# AE822FA0E5597BS0_CM55_HE_View register map
Vendor: Alif Semiconductor; Series: E8; File version: 1.0
CPU: CM55 r1p0, selectable endian, MPU, FPU, double-precision FPU, DSP, VTOR, 8 interrupt priority bits, 1 SAU regions
Registers are 32-bit, read-write, reset 0x0 unless marked. A register's access mark holds for its fields unless they carry their own. Offsets are from the block's base; [hi:lo] are bit positions; {n}, {i} and the like mark numbered series.

## USB (part 1 of 2)
Base 0x48200000
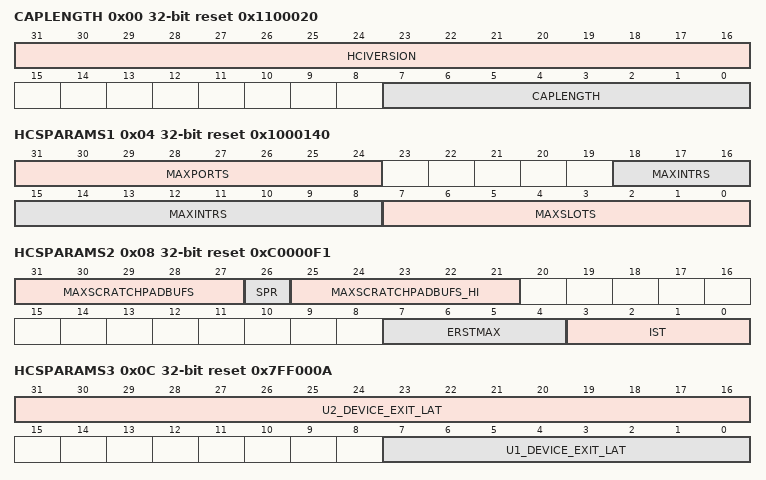
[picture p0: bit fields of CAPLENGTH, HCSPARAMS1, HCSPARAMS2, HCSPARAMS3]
0x00 CAPLENGTH ro reset 0x1100020 — Capability Registers Length
  [31:16] HCIVERSION — Host controller interface version number.
  [7:0] CAPLENGTH — Capability registers length.
0x04 HCSPARAMS1 ro reset 0x1000140 — Structural Parameters 1 Register
  [31:24] MAXPORTS — Number of ports.
  [18:8] MAXINTRS — Number of interrupters.
  [7:0] MAXSLOTS — Number of device slots.
0x08 HCSPARAMS2 ro reset 0xC0000F1 — Structural Parameters 2 Register
  [31:27] MAXSCRATCHPADBUFS — Maximum scratchpad buffers low. Possible values are from 0x1 to 0x4.
  [26] SPR — Scratchpad restore.
  [25:21] MAXSCRATCHPADBUFS_HI — Maximum scratchpad buffers high.
  [7:4] ERSTMAX — Event ring segment table maximum.
  [3:0] IST — Isochronous scheduling threshold.
0x0C HCSPARAMS3 ro reset 0x7FF000A — Structural Parameters 3 Register
  [31:16] U2_DEVICE_EXIT_LAT — U2 device exit latency.
  [7:0] U1_DEVICE_EXIT_LAT — U1 device exit latency.
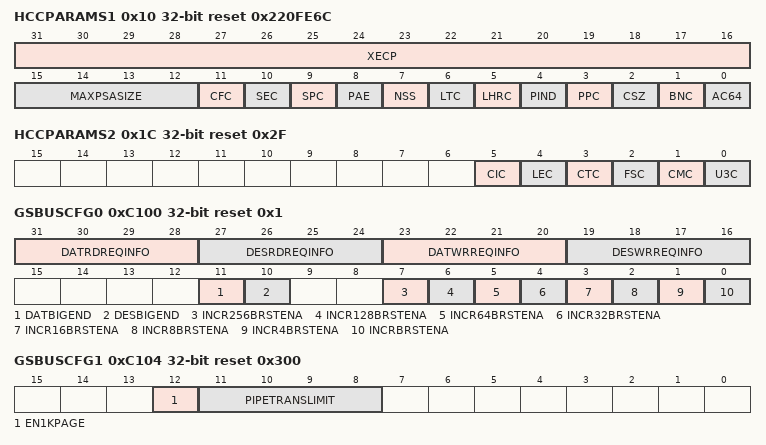
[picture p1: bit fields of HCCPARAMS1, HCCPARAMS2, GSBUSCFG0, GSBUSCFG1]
0x10 HCCPARAMS1 ro reset 0x220FE6C — Capability Parameters 1 Register
  [31:16] XECP — xHCI extended capabilities pointer.
  [15:12] MAXPSASIZE — Maximum primary stream array size.
  [11] CFC — Contiguous frame ID capability.
  [10] SEC — Stopped EDLTA capability.
  [9] SPC — Short packet capability.
  [8] PAE — Parse all event data.
  [7] NSS — No secondary SID support.
  [6] LTC — Latency tolerance messaging capability.
  [5] LHRC — Light host controller reset capability.
  [4] PIND — Port indicators.
  [3] PPC — Port power control.
  [2] CSZ — Context size.
  [1] BNC — Bandwidth negotiation capability.
  [0] AC64 — 64-bit addressing capability.
0x14 DBOFF ro reset 0x480 — Doorbell Offset
  [31:2] DOORBELL_ARRAY_OFFSET
0x18 RTSOFF ro reset 0x440 — Run-time Register Space Offset
  [31:5] RUNTIME_REG_SPACE_OFFSET — Runtime register space offset.
0x1C HCCPARAMS2 ro reset 0x2F — Host Controller Capability Parameters 2
  [5] CIC — Configuration information capability.
  [4] LEC — Large ESIT payload capability.
  [3] CTC — Compliance transition capability.
  [2] FSC — Force save context capability.
  [1] CMC — Configure endpoint command maximum exit latency too large capability.
  [0] U3C — U3 entry capability.
0xC100 GSBUSCFG0 reset 0x1 — Global SoC Bus Configuration Register 0
  [31:28] DATRDREQINFO — Data read request info. AHB-prot/AXI-cache/OCP-ReqInfo for data read.
  [27:24] DESRDREQINFO — Descriptor read request info. AHB-prot/AXI-cache/OCP-ReqInfo for descriptor read.
  [23:20] DATWRREQINFO — Data write request info. AHB-prot/AXI-cache/OCP-ReqInfo for data write.
  [19:16] DESWRREQINFO — Descriptor write request info. AHB-prot/AXI-cache/OCP-ReqInfo for descriptor write.
  [11] DATBIGEND — Data access is big endian. This bit controls the endian mode for data accesses. Note: For an AXI master, this bit must be set to 0x0.
    0=Little-endian (default); 1=Big-endian
  [10] DESBIGEND — Descriptor access is big endian. This bit controls the endian mode for descriptor accesses. Data is considered as embedded data in the descriptors in the following cases: - Device mode: The buffer pointer of a Setup TRB points to the Setup TRB itself. In device mode, if the system uses different endian modes for descriptor and data, software must not use embedded data. - Host mode: The Immediate Data (IDT) bit in a Transfer TRB is set to 0x1. In host mode, if the system uses different endian modes for data and descriptors, the controller treats embedded data as descriptor (not as data) in terms of endian mode handling. If this is not the expectation of the system, the software must manipulate the embedded data accordingly. Note: For an AXI master, this bit must be set to 0x0.
    0=Little-endian (default); 1=Big-endian
  [7] INCR256BRSTENA — INCR256 burst type enable. If software set this bit to 0x1, the AXI master uses INCR to do the 256-beat burst.
  [6] INCR128BRSTENA — INCR128 burst type enable. If software set this bit to 0x1, the AXI master uses INCR to do the 128-beat burst.
  [5] INCR64BRSTENA — INCR64 burst type enable. If software set this bit to 0x1, the AXI master uses INCR to do the 64-beat burst.
  [4] INCR32BRSTENA — INCR32 burst type enable. If software set this bit to 0x1, the AXI master uses INCR to do the 32-beat burst.
  [3] INCR16BRSTENA — INCR16 burst type enable. If software set this bit to 0x1, the AXI master uses INCR to do the 16-beat burst.
  [2] INCR8BRSTENA — INCR8 burst type enable. If software set this bit to 0x0, the AXI master uses INCR to do the 8-beat burst.
  [1] INCR4BRSTENA — INCR4 burst type enable. When this bit is enabled (set to 0x1), the controller is allowed to do bursts of beat length 1, 2, and 4. It is highly recommended that this bit is enabled to prevent descriptor reads and writes from being broken up into separate transfers.
  [0] INCRBRSTENA — Undefined length INCR burst type enable. This bit determines the set of burst lengths the master interface uses. It works in conjunction with the GSBUSCFG0[7-1] bits enables (INCR256/128/64/32/16/8/4). ARLEN/AWLEN do not use INCR except in case of non-aligned burst transfers. In the case of address-aligned transfers, they use only the following burst lengths: - 1 - 2, 4 (if GSBUSCFG0[INCR4BRSTENA] = 0x1) - 8 (if GSBUSCFG0[INCR8BRSTENA] = 0x1) - 16 (if GSBUSCFG0[INCR16BRSTENA] = 0x1) - 32 (if GSBUSCFG0[INCR32BRSTENA] = 0x1) - 64 (if GSBUSCFG0[INCR64BRSTENA] = 0x1) - 128 (if GSBUSCFG0[INCR128BRSTENA] = 0x1) - 256 (if GSBUSCFG0[INCR256BRSTENA] = 0x1) Note: In case of non-address-aligned transfers, INCR may get generated at the beginning and end of the transfers to align the address boundaries, even though INCR is disabled. AXI: ARLEN/AWLEN uses any length less than or equal to the largest-enabled burst length of INCR32/64/128/256.
    0=INCRX burst mode; 1=INCR (undefined length) burst mode
0xC104 GSBUSCFG1 reset 0x300 — Global SoC Bus Configuration Register 1
  [12] EN1KPAGE — 1KB page boundary. By default (this bit is disabled) the AXI breaks transfers at the 4KB page boundary. When this bit is enabled, the AXI master (DMA data) breaks transfers at the 1KB page boundary.
  [11:8] PIPETRANSLIMIT — AXI pipelined transfers burst request limit. This bit field controls the number of outstanding pipelined transfer requests the AXI master pushes to the AXI slave. When the AXI master reaches this limit, it does not make any more requests on the AXI ARADDR and AWADDR buses until the associated data phases complete. This bit field is encoded as follows:
    0=1 request; 1=2 requests; 2=3 requests; 3=4 requests; 15=16 requests
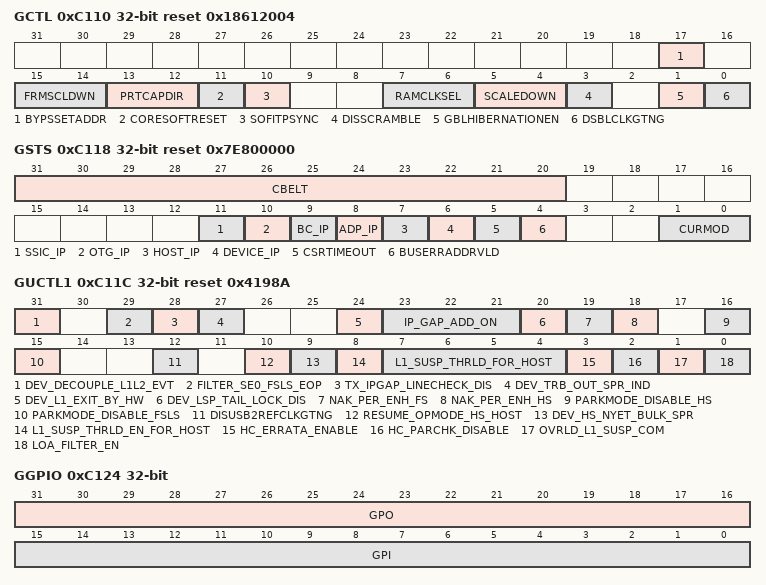
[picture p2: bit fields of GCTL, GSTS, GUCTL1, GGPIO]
0xC110 GCTL reset 0x18612004 — Global Core Control Register
  [17] BYPSSETADDR — Bypass set address in Device mode. This bit must be set to 0x0.
  [15:14] FRMSCLDWN — Frame scales down. This bit field scales down device view of a SOF/USOF/ITP duration. For High Speed (HS) mode: - Value of 3 implements interval to be 15.625 us - Value of 2 implements interval to be 31.25 us - Value of 1 implements interval to be 62.5 us - Value of 0 implements interval to be 125 us
  [13:12] PRTCAPDIR — Port capability direction. Note: For static Host-only/Device-only applications, use DRD Host or DRD Device mode. The combination of this bit filed set to 0x3 with SRP and HNP/RSP disabled is not recommended for these applications. The sequence for switching modes in DRD Device mode is as follows: - For switching from Device to Host: 1. Reset the controller using the CORESOFTRESET bit. 2. Set the PRTCAPDIR bit field to 0x1 (Host mode). 3. Reset the host using USBCMD.HCRESET bit. 4. Follow the steps in Section Initializing Host Registers. - For switching from Host to Device: 1. Reset the controller using the CORESOFTRESET bit. 2. Set the GCTL[PRTCAPDIR] bit field to 0x2 (Device mode). 3. Reset the device by setting the DCTL[CSFTRST] bit. 4. Follow the steps in Section Initializing Registers. Programming this bit field with random data causes the controller to keep toggling between the Host mode and the Device mode. Bit Bash register testing is not recommended.
    1=For host configurations; 2=For device configurations
  [11] CORESOFTRESET — Core soft reset. Clears the interrupts and all the CSRs except the following registers: - GCTL - GUCTL - GSTS - GSNPSID - GUID - GUSB2PHYCFG0 - DCFG - DCTL - DEVTEN - DSTS Note: This bit is for debug purposes only. Use USBCMD.HCRESET bit in xHCI Mode and the DCTL[SOFTRESET] bit in Device mode for soft reset. Programming this bit field with random data will reset the internal logic of the host controller. Due to this side effect Bit Bash register testing is not recommended.
    0=No soft reset; 1=Soft reset to controller
  [10] SOFITPSYNC — Reserved.
  [7:6] RAMCLKSEL — RAM clock (RAM_CLK) select.
    0=AHB bus clock (BUS_CLK); 2=In Host mode, the controller switches RAM_CLK between MAC2_CLK and BUS_CLK based on the status of the USB ports; 3=In Device mode, selects MAC2_CLK as RAM_CLK. In Host mode, controller switches RAM_CLK between MAC2_CLK and BUS_CLK based on the status of the USB ports.
  [5:4] SCALEDOWN — Scale-Down mode. Keep at 0x0.
  [3] DISSCRAMBLE — Disable scrambling.
  [1] GBLHIBERNATIONEN ro — Hibernation enable status at the global level. If hibernation is not enabled through this bit, the PMU immediately accepts the D0 -> D3 and D3 -> D0 power state change requests, but does not save or restore any controller state. In addition, the PMUs never drive the PHY interfaces and let the controller continue to drive the PHY interfaces.
  [0] DSBLCLKGTNG — Disable clock gating. This bit is set to 0x1 and the controller is in Low-Power mode, internal clock gating is disabled. This bit can be set to 0x1 after power-on reset.
0xC118 GSTS reset 0x7E800000 — Global Status Register
  [31:20] CBELT ro — Current BELT value. In Host mode, this bit field indicates the minimum value of all received device BELT values and the BELT value that is set by the Set Latency Tolerance Value command.
  [11] SSIC_IP ro — This bit is not used.
  [10] OTG_IP ro — This bit is not used.
  [9] BC_IP ro — This bit is not used.
  [8] ADP_IP ro — This bit is not used.
  [7] HOST_IP ro — Host interrupt pending. This field indicates that there is a pending interrupt pertaining to xHC in the Host event queue.
  [6] DEVICE_IP ro — Device interrupt pending. This field indicates that there is a pending interrupt pertaining to peripheral (device) operation in the Device event queue.
  [5] CSRTIMEOUT — CSR timeout. When this bit is set to 0x1, it indicates that the software performed a write or read to a controller register that could not be completed within predefined bus clock cycles (default: 0x1FFFF). Write 0x1 to clear.
  [4] BUSERRADDRVLD — Bus error address valid. Indicates that the Global SoC Bus Error Address register (GBUSERRADDRLO or GBUSERRADDRHI) is valid and reports the first bus address that encounters a bus error. Write 0x1 to clear.
  [1:0] CURMOD ro — Indicates the current mode of operation.
    0=Device mode; 1=Host mode
0xC11C GUCTL1 reset 0x4198A — Global User Control Register 1
  [31] DEV_DECOUPLE_L1L2_EVT — Device decoupled L1/L2 event. This bit is applicable for Device mode only. If this feature is enabled, L1 suspend and wake events have individual controls to enable/mask them.
    0=Default behavior, no change in device events L1/L2 events are not decoupled; 1=Feature enabled, L1 and L2 events are separated. Separate event enable bits for L1 suspend and wake events.
  [29] FILTER_SE0_FSLS_EOP — Filter SE0 detection in FS/LS or EOP. This bit is applicable for FS/LS operation. If this feature is enabled, then SE0 on the LineState is validated for two consecutive UTMI clock edges for EOP detection. This feature is applicable only in FS in Device mode and FS/LS mode of operation in Host mode. - Device mode: FS-If this bit is set, then for device LPM handshake, the controller will ignore single SE0 glitch on the LineState during transmit. Only two or more SE0 is considered as a valid EOP on FS. - Host mode: FS/LS-If FILTER_SE0_FSLS_EOP is set, then the controller will ignore single SE0 glitch on the LineState during transmit. Only two or more SE0 is considered as a valid EOP on FS/LS port. Enable this feature if the LineState has SE0 glitches during transmission. This bit is quasi-static, that is, it must not be changed during device operation.
    0=Default behavior, no change in LineState check for SE0 detection in FS/LS; 1=Feature enabled, FS/LS SE0 is filtered for two clocks for detecting EOP
  [28] TX_IPGAP_LINECHECK_DIS — Disable TX IPGAP LineState check. This bit is applicable for HS operation of MAC. If this feature is enabled, then the MAC operating in HS ignores the UTMI/ULPI LineState during the transmit of a token (during token-to-token and token-to-data IPGAP). When enabled, the controller implements a fixed 40-bit TXENDDELAY after the packet is given on UTMI and ignores the LineState during this time: - Device mode: If this bit is set, then for device LPM handshake, the controller will ignore the LineState after TX and wait for fixed clocks (40 bit times equivalent) after transmitting ACK on UTMI. - Host mode: If this bit is set, then the IPGAP between (token-to-token/token-to-data) is added by 40 bit times of TXENDDELAY, and LineState is ignored during this 40 bit times delay. Enable this bit if the LineState will not reflect the expected line state (J) during transmission. This bit is quasi-static, that is, it must not be changed during device operation.
    0=Default behavior, no change in LineState check; 1=Feature enabled, 2.0 MAC disables LineState check during HS transmit
  [27] DEV_TRB_OUT_SPR_IND — OUT in TRB status short packet indication. This bit is applicable for Device mode only. If the device application (software/hardware) wants to know if a short packet was received for an OUT in the TRB status itself, then this feature can be enabled, so that a bit is set in the TRB writeback in the BUF_SIZE DWORD. The HCSPARAMS2[SPR] bit of the {trbstatus, RSVD, SPR, PCM1, bufsize} DWORD will be set during an OUT transfer TRB write back if this is the last TRB used for that transfer descriptor. This bit is quasi-static, that is, it must not be changed during device operation.
    0=Default behavior, no change in TRB status DWORD; 1=Feature enabled, OUT TRB status indicates Short Packet
  [24] DEV_L1_EXIT_BY_HW — Device in L1 hardware exit. When control transfers are in progress, the LPM is rejected (NYET response). Only after control transfers are completed (either with ACK/STALL), LPM is accepted. This bit is applicable for Device mode only. This field enables device controller sending remote wakeup for L1 if the device becomes ready for sending/accepting data when in L1 state. If the host expects the device to send remote wakeup signaling to resume after going into L1 in flow controlled state, then this bit can be set to send the remote wake signal automatically when the device controller becomes ready. This hardware remote wake feature is applicable only to bulk and interrupt transfers, and not for isochronous/control. For isochronous transfers, the host needs to do the wake-up and start the transfer. Device controller will not do remote-wakeup when isochronous endpoints get ready. The device software needs to keep the GUSB2PHYCFG0[ENBLSLPM] bit reset in order to keep the PHY clock to be running for keeping track of SOF intervals.
    0=Default behavior, disables device L1 hardware exit logic; 1=Feature is enabled
  [23:21] IP_GAP_ADD_ON — Inter packet gap add on. This bit field is used to add on to the default inter packet gap setting in the USB 2.0 MAC. This should be programmed to a non-zero value only in case where it is need to increase the default inter packet delay calculations in the USB 2.0 MAC
  [20] DEV_LSP_TAIL_LOCK_DIS — Disable device LSP lock logic for tail TRB.
    0=Default behavior, enables device LSP lock logic for tail TRB update; 1=Fix is disabled
  [19] NAK_PER_ENH_FS — Performance enhancement for FS in NAK. If a periodic endpoint is present, and if a bulk endpoint which is also active is being NAKed by the device, then this could result in a decrease in performance of other Full-Speed bulk endpoint which is ACKed by the device. Setting this bit to 0x1, enables the HC to schedule more transactions to the async endpoints (bulk/control) and hence improves the performance of the bulk endpoint. This control bit should be enabled only if the existing performance with the default setting is not sufficient for Full-Speed application. Setting this bit will only control, and is only required for Full-Speed transfers.
    0=Enhancement not applied; 1=Enables performance enhancement for FS async endpoints in the presence of NAKs
  [18] NAK_PER_ENH_HS — Performance enhancement for HS in NAK. If a periodic endpoint is present, and if a bulk endpoint which is also active is being NAKed by the device, then this could result in decrease in performance of other HS bulk endpoint which is ACked by the device. Setting this bit to 0x1, enables the host controller to schedule more transactions to the async endpoints (bulk/control) and hence it improves the performance of the bulk endpoint. This control bit should be enabled only if the existing performance with the default setting is not sufficient for HS application. Setting this bit only controls, and is only required for HS transfers.
    0=Enhancement not applied; 1=Enables performance enhancement for HS async endpoints in the presence of NAKs
  [16] PARKMODE_DISABLE_HS — Disable park mode of HS bus instances. This bit is used only in Host mode. When this bit is set to 0x1, all HS bus instances park mode are disabled. To improve performance in park mode, the xHCI scheduler queues in three requests of 4 packets each for HS asynchronous endpoints in a micro-frame. But if a device is slow and if it NAKs more than 3 times, then it is rescheduled only in the next micro-frame. This could decrease the performance of a slow device even further.
  [15] PARKMODE_DISABLE_FSLS — Disable park mode of FS/LS bus instances. This bit is used only in Host mode, and is for debug purpose only. When this bit is set to 0x1 all FS/LS bus instances in park mode disabled.
  [12] DISUSB2REFCLKGTNG ro — Disable REF_CLK gating for 2.0 PHY If REF_CLK gating is disabled, then the REF_CLK input cannot be turned off to the USB 2.0 PHY and controller. This is independent of the GCTL[DSBLCLKGTNG] bit setting.
    0=REF_CLK gating enabled for USB 2.0 PHY; 1=REF_CLK gating disabled for USB 2.0 PHY
  [10] RESUME_OPMODE_HS_HOST — Opmode in HS resume in Host mode This bit is used only in Host mode, and is for USB 2.0 opmode behavior in HS Resume.
    0=When this bit is set to 0x0, the UTMI/ULPI opmode changes to normal 2 us after HS terminations change after EOR. This is the default behavior.; 1=When this bit is set to 0x1, the UTMI opmode changes to normal along with HS terminations after EOR
  [9] DEV_HS_NYET_BULK_SPR — HS bulk OUT short packet gets NYET in Device mode This bit is applicable for Device mode only. If this bit is set, the device controller sends NYET response instead of ACK response for a successfully received bulk OUT short packet. If NYET is sent after receiving short packet, then the host would PING before sending the next OUT; this improves the performance as well as clears up the buffer/cache on the host side. Internal to the device controller, short packet (HCSPARAMS2[SPR] = 0x1) processing takes some time, and during this time, the USB is flow controlled. With NYET response instead of ACK on short packet, the host does not send another OUT-DATA without pinging in HS mode. This bit is quasi-static, that is, it must not be changed during device operation.
    0=Default behavior, no change in device response; 1=Feature enabled, HS bulk OUT short packet gets NYET response
  [8] L1_SUSP_THRLD_EN_FOR_HOST — L1 suspend threshold enable in Host mode. This bit is used only in Host mode. The host controller asserts the UTMI_L1_SUSPEND_n and UTMI_SLEEP_n output signals as follows: The controller asserts the UTMI_L1_SUSPEND_n signal to put the PHY into deep low-power mode in L1 when both of the following are true: a) The HIRD/BESL value used is greater than or equal to the value in the L1_SUSP_THRLD_FOR_HOST bit. b) The L1_SUSP_THRLD_EN_FOR_HOST bit is set to 0x1. The controller asserts UTMI_SLEEP_n on L1 when one of the following is true: a) The HIRD/BESL value used is less than the value in the L1_SUSP_THRLD_FOR_HOST bit. b) This bit is set to 0x0.
  [7:4] L1_SUSP_THRLD_FOR_HOST — L1 suspend threshold in Host mode. This bit field is effective only when the L1_SUSP_THRLD_EN_FOR_HOST bit is set to 0x1. For more details, refer to the description of the L1_SUSP_THRLD_EN_FOR_HOST bit.
  [3] HC_ERRATA_ENABLE — Host Exit Latency Delta (ELD) enable. When this bit is set to 0x1, it enables the ELD support defined in the xHCI 1.0 Errata. This bit is used only in Host mode and should be set to 0x1.
  [2] HC_PARCHK_DISABLE — Host parameter check disable. When this bit is set to 0x0 (by default), the xHC checks that the input slot/EP context fields comply to the xHCI Specification. Upon detection of a parameter error during command execution, the xHC generates an event TRB with completion code indicating PARAMETER_ERROR. When the bit is set to 0x1, the xHC does not perform parameter checks and does not generate PARAMETER_ERROR completion code.
  [1] OVRLD_L1_SUSP_COM — Overvload UTMI_L1_SUSPEND_COM. If this bit is set, the UTMI_L1_SUSPEND_COM_n is overloaded with the UTMI_SLEEP_n signal. This bit is usually set if the PHY stops the port clock during L1 sleep condition.
  [0] LOA_FILTER_EN — LOA filter enable. If this bit is set, the USB 2.0 port babble is checked at least three consecutive times before the port is disabled. This prevents false triggering of the babble condition when using low quality cables. Note: This bit is valid only in Host mode.
0xC120 GSNPSID ro reset 0x5533330B — Global Controller ID Register
  [31:0] GSNPSID — The GSNPSID[31-16] bit field indicates the Core Identification Number. 0x5533 is ASCII for U3. The GSNPSID[15-0] bit field indicates the release number. Current Release is 3.30b.
0xC124 GGPIO — Global General Purpose Input/Output Register
  [31:16] GPO — General-purpose output. The value of this field is driven out on the GP_OUT[15:0] output port.
  [15:0] GPI ro — General-purpose input. The read value of this field reflects the GP_IN[15:0] input signal value. Note: Register bit-bash test should not check for reset value of this field since its not predictable; depends on the GP_IN port.
0xC128 GUID reset 0x12345678 — Global User ID Register
  [31:0] USERID — Application-programmable ID field.
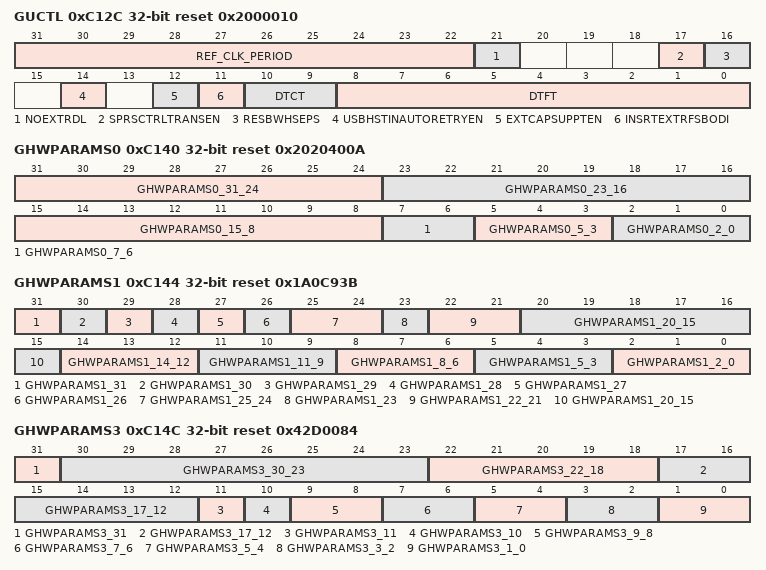
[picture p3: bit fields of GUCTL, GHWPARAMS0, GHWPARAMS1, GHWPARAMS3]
0xC12C GUCTL reset 0x2000010 — Global User Control Register
  [31:22] REF_CLK_PERIOD — REF_CLK period. This bit field indicates in terms of nano seconds the period of REF_CLK. The default value of this bit field is set to 0x8 (8 ns/125 MHz). This bit field needs to be updated during power-on initialization, if the GCTL[SOFITPSYNC] or GFLADJ[GFLADJ_REFCLK_LPM_SEL] bit is set to 0x1. The programmable maximum value is 62 ns, and the minimum value is 8 ns. The user should use a reference clock with a period that is an integer multiple, so that ITP can meet the jitter margin of 32 ns. The allowable REF_CLK frequencies whose period is not integer multiples are 16/17/19.2/24/39.7 MHz. This bit field must not be set to 0x0 at any time. If it is not planed to use this feature, this bit field should be set to 0x8 (the default value).
  [21] NOEXTRDL — No Extra Delay Between SOF and the First Packet. Some HS devices misbehave when the host sends a packet immediately after a SOF. However, adding an extra delay between a SOF and the first packet can reduce the USB data rate and performance. This bit is used to control whether the host must wait for 2 us before it sends the first packet after a SOF, or not. This bit can be set to 0x1 to improve the performance if those problematic devices are not a concern in the user host environment.
    0=Host waits for 2 us after a SOF before it sends the first USB packet; 1=Host does not wait after a SOF before it sends the first USB packet
  [17] SPRSCTRLTRANSEN — Sparse control transaction enable. Some devices are slow in responding to control transfers. Scheduling multiple transactions in one microframe/frame can cause these devices to misbehave. If this bit is set to 0x1, the HC schedules transactions for a control transfer in different microframes/frames.
  [16] RESBWHSEPS — Reserving 85% bandwidth for HS periodic EPs. By default, HC reserves 80% of the bandwidth for periodic EPs. If this bit is set, the bandwidth is relaxed to 85% to accommodate two High-Speed, High-Bandwidth ISOC EPs. USB 2.0 requires 80% bandwidth allocated for ISOC traffic. If two High-Bandwidth ISOC devices (HD webcams) are connected, and if each requires 1024 bytes x 3 packets per Micro-Frame, then the bandwidth required is around 82%. If this bit is set, then it is possible to connect two webcams of 1024 bytes x 3 payload per Micro-Frame each. Otherwise, it could be needed to reduce the resolution of the webcams. Note: This bit is used in Host mode operation only. Ignore this bit in Device mode.
  [14] USBHSTINAUTORETRYEN — Host IN auto retry. When set, this bit enables the Auto Retry feature. For IN transfers (non-isochronous) that encounter data packets with CRC errors or internal overrun scenarios, the Auto Retry feature causes the HC to reply to the device with a non-terminating retry ACK (that is, an ACK transaction packet with Retry = 1 and NumP != 0). If the Auto Retry feature is disabled (default), the controller responds with a terminating retry ACK (that is, an ACK transaction packet with Retry = 1 and NumP = 0). Note: When enabling Auto Retry feature, if the system latency is large enough to cause the internal PSQ full (PSQ can be full as the result of messages not being processed because of pending fetches before flushing the TxQ due to NRDY/ERDY conditions), then the HC can generate a transaction error.
    0=Auto Retry is disabled; 1=Auto Retry is enabled
  [12] EXTCAPSUPPTEN — External extended capability support enable. When set, this bit enables extended capabilities to be implemented outside the controller.
  [11] INSRTEXTRFSBODI — Insert extra delay between FS Bulk OUT transactions. Some FS devices are slow to receive Bulk OUT data and can get stuck when there are consecutive Bulk OUT transactions with short inter-transaction delays. This bit is used to control whether the host inserts extra delay between consecutive Bulk OUT transactions to a FS Endpoint. Note: Setting this bit to 0x1 reduces the Bulk OUT transfer performance for most of the FS devices.
    0=Host does not insert extra delay between consecutive Bulk OUT transactions to a FS Endpoint; 1=Host inserts about 12 us extra delay between consecutive Bulk OUT transactions to a FS Endpoint to work around the device issue
  [10:9] DTCT — Device timeout coarse tuning. This field is a Host mode parameter which determines how long the host waits for a response from device before considering a timeout. The controller first checks the DTCT value. If it is 0x0, then the timeout value is defined by the DTFT. If it is non-zero, then it uses the following timeout values: Note: When the system latency is larger than the programmed DTCT/DTFT value, if the HC is not able to accept certain transactions on the bus (because of system bus delays), the controller may not release header credits which in turn can cause the host to report a transaction error. Therefore, program this value to be larger than your system delay.
    0=0 us-use DTFT value instead; 1=500 us; 2=1.5 ms; 3=6.5 ms
  [8:0] DTFT — Device timeout fine tuning. This bit field is a Host mode parameter which determines how long the host waits for a response from device before considering a timeout. For the DTFT field to take effect, the DTCT bit filed must be set to 0x0. The DTCT value is the number of 60 MHz clocks x 256 to count before considering a device timeout. The minimum value of DTFT is 0x2. Note: When the system latency is larger than the programmed DTCT/DTFT value, if the HC is not able to accept certain transactions on the bus (because of system bus delays), the controller may not release header credits which in turn can cause the host to report a transaction error. Therefore, program this value to be larger than your system delay.
0xC130 GBUSERRADDRLO ro — Global SoC Bus Error Address Register-Low
  [31:0] BUSERRADDR — Bus address-low. This register contains the lower 32 bits of the first bus address that encountered a SoC bus error. It is valid when the GSTS[BUSEEEADDRVLD] bit is set to 0x1. It can only be cleared by resetting the controller.
0xC134 GBUSERRADDRHI ro — Global SoC Bus Error Address Register-High
  [31:0] BUSERRADDR — Bus address-high. This register contains the higher 32 bits of the first bus address that encountered a SoC bus error. It is valid when the GSTS[BUSERRADDRVLD] bit is set to 0x1. It can only be cleared by resetting the controller.
0xC140 GHWPARAMS0 ro reset 0x2020400A — Global Hardware Parameters Register 0
  [31:24] GHWPARAMS0_31_24 — Master/Slave Address Bus Width (num bits).
  [23:16] GHWPARAMS0_23_16 — Slave Bus (Register Access Bus) Data Bus Width (num bits).
  [15:8] GHWPARAMS0_15_8 — Master Bus (DMA Bus) Data Bus Width (num bits).
  [7:6] GHWPARAMS0_7_6 — Slave Bus (Register Access Bus) Interface Type (0x0 = AHB).
  [5:3] GHWPARAMS0_5_3 — Master Bus (DMA Bus) Interface Type (0x1 = AXI).
  [2:0] GHWPARAMS0_2_0 — Mode of Operation (0x2 = Device and Host (DRD)).
0xC144 GHWPARAMS1 ro reset 0x1A0C93B — Global Hardware Parameters Register 1
  [31] GHWPARAMS1_31 — xHCI debug capability.
  [30] GHWPARAMS1_30 — RM_OPT_FEATURES
  [29] GHWPARAMS1_29 — Reserved.
  [28] GHWPARAMS1_28 — RAM_BUS_CLKS_SYNC
  [27] GHWPARAMS1_27 — MAC_RAM_CLKS_SYNC
  [26] GHWPARAMS1_26 — MAC_PHY_CLKS_SYNC
  [25:24] GHWPARAMS1_25_24 — Power Optimization Mode (0x1 = Clock Gating Only)
  [23] GHWPARAMS1_23 — Synchronous Static RAM Type (0x1 = Single-Port RAM (SPRAM))
  [22:21] GHWPARAMS1_22_21 — Number of RAMs
  [20:15] GHWPARAMS1_20_15 — Number of Device Mode Event Buffers
  [14:12] GHWPARAMS1_14_12 — ASPACEWIDTH
  [11:9] GHWPARAMS1_11_9 — REQINFOWIDTH
  [8:6] GHWPARAMS1_8_6 — DATAINFOWIDTH
  [5:3] GHWPARAMS1_5_3 — BURSTWIDTH - 1
  [2:0] GHWPARAMS1_2_0 — IDWIDTH - 1
0xC148 GHWPARAMS2 ro reset 0x12345678 — Global Hardware Parameters Register 2
  [31:0] GHWPARAMS2_31_0 — User ID
0xC14C GHWPARAMS3 ro reset 0x42D0084 — Global Hardware Parameters Register 3
  [31] GHWPARAMS3_31 — Reserved.
  [30:23] GHWPARAMS3_30_23 — CACHE_TOTAL_XFER_RESOURCES
  [22:18] GHWPARAMS3_22_18 — Number of Device Mode Active IN Endpoints
  [17:12] GHWPARAMS3_17_12 — Number of Device Mode Endpoints
  [11] GHWPARAMS3_11 — ULPI_CARKIT
  [10] GHWPARAMS3_10 — UTMI PHY Vendor Control Interface
  [9:8] GHWPARAMS3_9_8 — Reserved.
  [7:6] GHWPARAMS3_7_6 — HSPHY_DWIDTH
  [5:4] GHWPARAMS3_5_4 — FSPHY_INTERFACE
  [3:2] GHWPARAMS3_3_2 — HSPHY_INTERFACE (0x1 = UTMI+)
  [1:0] GHWPARAMS3_1_0 — SSPHY_INTERFACE
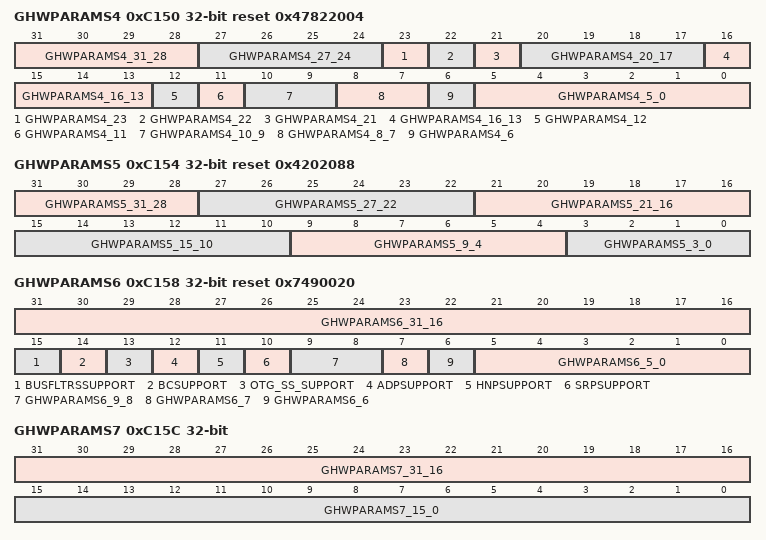
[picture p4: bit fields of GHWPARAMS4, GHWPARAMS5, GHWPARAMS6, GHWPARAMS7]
0xC150 GHWPARAMS4 ro reset 0x47822004 — Global Hardware Parameters Register 4
  [31:28] GHWPARAMS4_31_28 — BMU_LSP_DEPTH
  [27:24] GHWPARAMS4_27_24 — BMU_PTL_DEPTH-1
  [23] GHWPARAMS4_23 — EN_ISOC_SUPT
  [22] GHWPARAMS4_22 — Reserved.
  [21] GHWPARAMS4_21 — Device External Buffer Control
  [20:17] GHWPARAMS4_20_17 — NUM_SS_USB_INSTANCES
  [16:13] GHWPARAMS4_16_13 — HIBER_SCRATCHBUFS
  [12] GHWPARAMS4_12 — Reserved.
  [11] GHWPARAMS4_11 — Reserved.
  [10:9] GHWPARAMS4_10_9 — Reserved.
  [8:7] GHWPARAMS4_8_7 — Reserved.
  [6] GHWPARAMS4_6 — Reserved.
  [5:0] GHWPARAMS4_5_0 — Number of cached TRBs per Transfer
0xC154 GHWPARAMS5 ro reset 0x4202088 — Global Hardware Parameters Register 5
  [31:28] GHWPARAMS5_31_28 — Reserved.
  [27:22] GHWPARAMS5_27_22 — DFQ_FIFO_DEPTH
  [21:16] GHWPARAMS5_21_16 — DWQ_FIFO_DEPTH
  [15:10] GHWPARAMS5_15_10 — TXQ_FIFO_DEPTH
  [9:4] GHWPARAMS5_9_4 — RXQ_FIFO_DEPTH
  [3:0] GHWPARAMS5_3_0 — BMU_BUSGM_DEPTH
0xC158 GHWPARAMS6 ro reset 0x7490020 — Global Hardware Parameters Register 6
  [31:16] GHWPARAMS6_31_16 — Total RAM0 Depth
  [15] BUSFLTRSSUPPORT — Filter for VBUS- and ID-related control inputs from the PHY
  [14] BCSUPPORT — Battery Charging Capability
  [13] OTG_SS_SUPPORT — Reserved.
  [12] ADPSUPPORT
  [11] HNPSUPPORT — Reserved.
  [10] SRPSUPPORT — Reserved.
  [9:8] GHWPARAMS6_9_8 — Reserved.
  [7] GHWPARAMS6_7 — Reserved.
  [6] GHWPARAMS6_6 — Reserved.
  [5:0] GHWPARAMS6_5_0 — PSQ_FIFO_DEPTH
0xC15C GHWPARAMS7 ro — Global Hardware Parameters Register 7
  [31:16] GHWPARAMS7_31_16 — RAM2_DEPTH
  [15:0] GHWPARAMS7_15_0 — RAM1_DEPTH
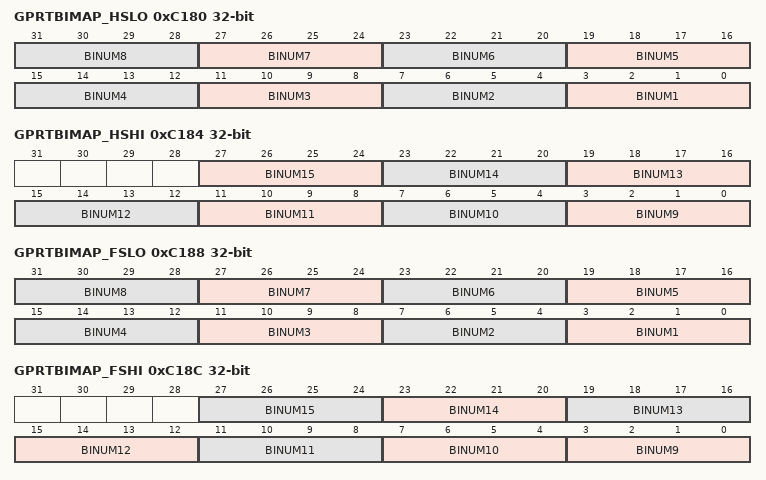
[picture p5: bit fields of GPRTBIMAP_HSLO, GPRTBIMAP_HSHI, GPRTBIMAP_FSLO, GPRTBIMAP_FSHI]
0xC180 GPRTBIMAP_HSLO — Global High-Speed Port to Bus Instance Mapping (Low)
  [4n-1:4n-4] BINUM{n} (n=1..8) — HS USB instance number for port {n}. Application-programmable ID field.
0xC184 GPRTBIMAP_HSHI — Global High-Speed Port to Bus Instance Mapping (High)
  [27:24] BINUM15 — HS USB instance number for port 15. Application-programmable ID field.
  [23:20] BINUM14 — HS USB instance number for port 14. Application-programmable ID field.
  [19:16] BINUM13 — HS USB instance number for port 13. Application-programmable ID field.
  [15:12] BINUM12 — HS USB instance number for port 12. SApplication-programmable ID field.
  [11:8] BINUM11 — HS USB instance number for port 11. Application-programmable ID field.
  [7:4] BINUM10 — HS USB instance number for port 10. Application-programmable ID field.
  [3:0] BINUM9 — HS USB instance number for port 9. Application-programmable ID field.
0xC188 GPRTBIMAP_FSLO — Global Full-Speed Port to Bus Instance Mapping (Low)
  [4n-1:4n-4] BINUM{n} (n=1..8) — FS USB instance number for port {n}. Application-programmable ID field.
0xC18C GPRTBIMAP_FSHI — Global Full-Speed Port to Bus Instance Mapping (High)
  [4n-33:4n-36] BINUM{n} (n=10..15) — FS USB instance number for port {n}. Application-programmable ID field
  [3:0] BINUM9 — FS USB instance number for port 9. Application-programmable ID field.
